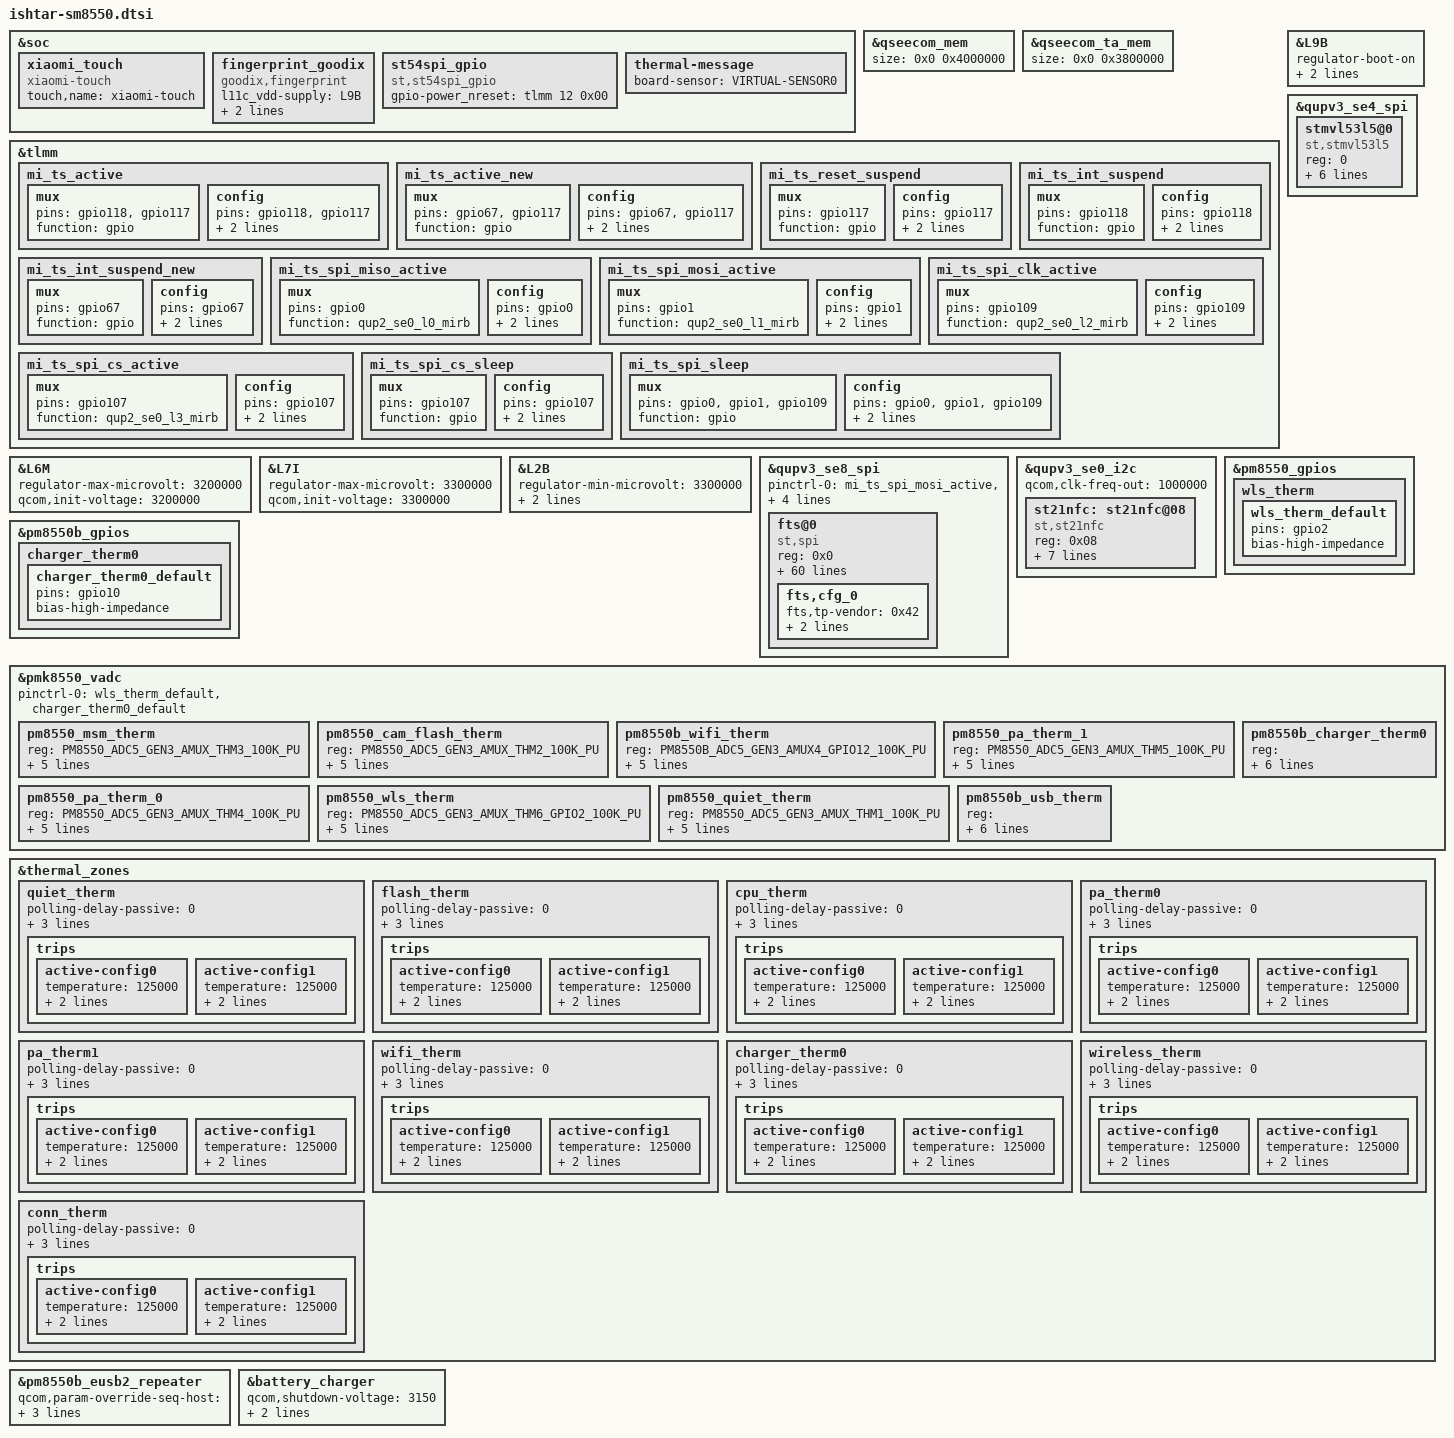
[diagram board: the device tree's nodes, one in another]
/*
  this file is for attribution only of zeus
  And public attribution of xiaomi platforms(like M1 and so and)
*/
#define ISHTAR_REGULATOR_OCP
#include "ishtar-pinctrl.dtsi"
#include "xiaomi-sm8550-common.dtsi"
#include <dt-bindings/clock/qcom,rpmh.h>

&soc {
	xiaomi_touch {
		compatible = "xiaomi-touch";
		status = "ok";
		touch,name = "xiaomi-touch";
	};
	fingerprint_goodix {
		compatible = "goodix,fingerprint";
		l11c_vdd-supply = <&L9B>;
		goodix,gpio-reset = <&tlmm 41 0x0>;
		goodix,gpio-irq = <&tlmm 40 0x0>;
		status = "ok";
	};
	st54spi_gpio {
		status = "ok";
		compatible = "st,st54spi_gpio";
		/* gpio used as SE_nRESET */
		gpio-power_nreset = <&tlmm 12 0x00>;
	};
};

&qseecom_mem {
		size = <0x0 0x4000000>;
};

&qseecom_ta_mem {
		size = <0x0 0x3800000>;
};

&tlmm {
	mi_ts_active: mi_ts_active {
		mux {
				pins = "gpio118", "gpio117";
				function = "gpio";
		};
		config {
				pins = "gpio118", "gpio117";
				drive-strength = <8>;
				bias-pull-up;
		};
	};

	mi_ts_active_new: mi_ts_active_new {
		mux {
				pins = "gpio67", "gpio117";
				function = "gpio";
		};
		config {
				pins = "gpio67", "gpio117";
				drive-strength = <8>;
				bias-pull-up;
		};
	};

	mi_ts_reset_suspend: mi_ts_reset_suspend {
		mux {
				pins = "gpio117";
				function = "gpio";
			};

		config {
				pins = "gpio117";
				drive-strength = <2>;
				bias-pull-down;
			};
	};

	mi_ts_int_suspend: mi_ts_int_suspend {
			mux {
				pins = "gpio118";
				function = "gpio";
			};

			config {
				pins = "gpio118";
				drive-strength = <2>;
				bias-pull-down;
			};
		};

	mi_ts_int_suspend_new: mi_ts_int_suspend_new {
		mux {
			pins = "gpio67";
			function = "gpio";
		};

		config {
			pins = "gpio67";
			drive-strength = <2>;
			bias-pull-down;
		};
	};

	mi_ts_spi_miso_active: mi_ts_spi_miso_active {
		mux {
			pins = "gpio0";
			function = "qup2_se0_l0_mirb";
		};
		config {
			pins = "gpio0";
			drive-strength = <6>;
			bias-pull-down;
		};
	};

	mi_ts_spi_mosi_active: mi_ts_spi_mosi_active {
		mux {
			pins = "gpio1";
			function = "qup2_se0_l1_mirb";
		};
		config {
			pins = "gpio1";
			drive-strength = <6>;
			bias-pull-down;
		};
	};

	mi_ts_spi_clk_active: mi_ts_spi_clk_active {
		mux {
			pins = "gpio109";
			function = "qup2_se0_l2_mirb";
		};
		config {
			pins = "gpio109";
			drive-strength = <6>;
			bias-pull-down;
		};
	};

	mi_ts_spi_cs_active: mi_ts_spi_cs_active {
		mux {
			pins = "gpio107";
			function = "qup2_se0_l3_mirb";
		};
		config {
			pins = "gpio107";
			drive-strength = <6>;
			bias-pull-down;
		};
	};

	mi_ts_spi_cs_sleep: mi_ts_spi_cs_sleep {
		mux {
			pins = "gpio107";
			function = "gpio";
		};
		config {
			pins =  "gpio107";
			drive-strength = <2>;
			bias-pull-up;
		};
	};

	mi_ts_spi_sleep: mi_ts_spi_sleep {
		mux {
			pins = "gpio0", "gpio1",
				"gpio109";
			function = "gpio";
		};
		config {
			pins = "gpio0", "gpio1",
				"gpio109";
			drive-strength = <2>;
			bias-pull-down;
		};
	};
};

&L9B {
	regulator-boot-on;
	regulator-always-on;
	qcom,init-voltage = <3008000>;
};

&L6M {
	regulator-max-microvolt = <3200000>;
	qcom,init-voltage = <3200000>;
};

&L7I {
	regulator-max-microvolt = <3300000>;
	qcom,init-voltage = <3300000>;
};

&L2B {
	regulator-min-microvolt = <3300000>;
	regulator-max-microvolt = <3300000>;
	qcom,init-voltage = <3300000>;
};

&qupv3_se4_spi {
	status = "ok";
	stmvl53l5@0 {
		compatible = "st,stmvl53l5";
		reg = <0>;
		_1P8_power-supply = <&L1B>;
		_3P0_power-supply = <&L2B>;
		spi-max-frequency = <8000000>;
		stm,interrupt = <&tlmm 85 1>;
		stm,l8_firmware_name = "stmvl53l8.bin";
		stm,l5_firmware_name = "stmvl53l5.bin";
		status = "ok";
	};
};



&qupv3_se8_spi {
	status = "ok";
	pinctrl-0 = <&mi_ts_spi_mosi_active>, <&mi_ts_spi_miso_active>,
				<&mi_ts_spi_clk_active>, <&mi_ts_spi_cs_active>;
	pinctrl-1 = <&mi_ts_spi_sleep>, <&mi_ts_spi_cs_sleep>;
	qcom,rt;
	fts@0 {
		status = "ok";
		compatible = "st,spi";
		reg = <0x0>;
		interrupt-parent = <&tlmm>;
		interrupts = <118 0x2008>;
		pinctrl-names = "pmx_ts_active", "pmx_ts_suspend", "pmx_ts_active_new", "pmx_ts_suspend_new";
		pinctrl-0 = <&mi_ts_active>;
		pinctrl-1 = <&mi_ts_int_suspend &mi_ts_reset_suspend>;
		pinctrl-2 = <&mi_ts_active_new>;
		pinctrl-3 = <&mi_ts_int_suspend_new &mi_ts_reset_suspend>;
		avdd-supply = <&L7I>;
		vdd-supply = <&L12B>;
		/*panel = <&dsi_k8_42_02_0a_dsc_cmd>;*/
		fts,pwr-reg-name = "avdd";
		fts,bus-reg-name = "vdd";
		fts,irq-gpio = <&tlmm  118 0x2008>;
		fts,irq-gpio,new = <&tlmm  67 0x2008>;
		fts,irq-gpio-name = "fts_irq";
		fts,reset-gpio-enable;
		fts,reset-gpio = <&tlmm 117 0x00>;
		fts,reset-gpio-name = "fts_rst";
		fts,irq-flags = <0x2008>;
		fts,x-max = <14400>;
		fts,y-max = <32000>;
		fts,fod-lx = <5850>;
		fts,fod-ly = <24060>;
		fts,fod-x-size = <2710>;
		fts,fod-y-size = <2710>;
		fts,support-fod;
		fts,support-thp;
		fts,support-thp-fw;
		spi-max-frequency = <12000000>;
		fts,support-super-resolution = <1>;
		fts,default-fw-name = "st_fts_m1.ftb";
		fts,config-array-size = <1>;
		fts,touch-follow-performance-def = <3>;
		fts,touch-tap-sensitivity-def = <4>;
		fts,touch-aim-sensitivity-def = <3>;
		fts,touch-tap-stability-def = <3>;
		fts,cornerfilter-area-step1 = <150>;
		fts,cornerfilter-area-step2 = <280>;
		fts,cornerfilter-area-step3 = <400>;
		fts,touch-deadzone-filter-ver = <2 0 0 0 0 0 0 0
										2 1 0 0 0 0 0 0
										2 2 0 0 0 3199 0 0
										2 3 1439 0 1439 3199 0 0>;
		fts,touch-deadzone-filter-hor = <2 0 0 0 1439 7 0 0
										2 1 0 3192 1439 3199 0 0
										2 2 0 0 0 3199 0 0
										2 3 1439 0 1439 3199 0 0>;
		fts,touch-edgezone-filter-ver = <1 0 0 0 0 0 0 0
										1 1 0 0 0 0 0 0
										1 2 0 0 60 3199 0 0
										1 3 1379 0 1439 3199 0 0>;
		fts,touch-edgezone-filter-hor = <1 0 0 0 1439 70 0 0
										1 1 0 3129 1439 3199 0 0
										1 2 0 0 60 3199 0 0
										1 3 1379 0 1439 3199 0 0>;
		fts,touch-cornerzone-filter-ver = <0 0 0 0 0 0 0 0
										0 1 0 0 0 0 0 0
										0 2 0 2799 250 3199 0 0
										0 3 1189 2799 1439 3199 0 0>;
		fts,touch-cornerzone-filter-hor1 = <0 0 0 0 280 280 0 0
										0 1 0 0 0 0 0 0
										0 2 0 2919 280 3199 0 0
										0 3 0 0 0 0 0 0>;
		fts,touch-cornerzone-filter-hor2 = <0 0 0 0 0 0 0 0
										0 1 1159 0 1439 280 0 0
										0 2 0 0 0 0 0 0
										0 3 1159 2919 1439 3199 0 0>;
		fts,touch-follow-performance = <10 15 1
										8 15 1
										6 15 1
										4 15 1
										2 15 1>;
		fts,touch-tap-sensitivity = <160 150 140 120 100>;
		fts,touch-aim-sensitivity = <10 8 6 4 2>;
		fts,touch-tap-stability = <8 12 15 18 25>;
		fts,touch-expert-array = <6 15 1 120 6 15
								  2 15 1 120 4 15
								  4 15 1 120 2 15>;
			fts,cfg_0 {
			fts,tp-vendor = <0x42>;
			fts,fw-name = "st_fts_m1.ftb";
			fts,limit-name = "stm_fts_production_limits.csv";
		};
	};
};


&qupv3_se0_i2c {
	status = "ok";
	qcom,clk-freq-out = <1000000>;
	#address-cells = <1>;
	#size-cells = <0>;
	st21nfc: st21nfc@08 {
		compatible = "st,st21nfc";
		reg = <0x08>;
		irq-gpios = <&tlmm 55 0x00>;
		reset-gpios = <&tlmm 30 0x00>;
		clkreq-gpios = <&tlmm 31 0x00>;
		interrupt-parent = <&tlmm>;
		interrupts = <55 0>;
		interrupt-names = "nfc_irq";
		pinctrl-names = "nfc_active", "nfc_suspend";
		pinctrl-0 = <&nfc_int_active &nfc_enable_active>;
		pinctrl-1 = <&nfc_int_suspend &nfc_enable_suspend>;
	};
};

&pm8550_gpios {
	wls_therm {
		wls_therm_default: wls_therm_default {
		pins = "gpio2";
		bias-high-impedance;
	};
	};
};

&pm8550b_gpios {
	charger_therm0 {
		charger_therm0_default: charger_therm0_default {
		pins = "gpio10";
		bias-high-impedance;
	};
	};
};

&pmk8550_vadc {
	pinctrl-names = "default";
	pinctrl-0 = <&wls_therm_default>, <&charger_therm0_default>;
	pm8550_msm_therm {
		reg = <PM8550_ADC5_GEN3_AMUX_THM3_100K_PU>;
		label = "pm8550_msm_therm";
		qcom,ratiometric;
		qcom,hw-settle-time = <200>;
		qcom,pre-scaling = <1 1>;
		qcom,adc-tm-type = <1>;
	};

	pm8550_cam_flash_therm {
		reg = <PM8550_ADC5_GEN3_AMUX_THM2_100K_PU>;
		label = "pm8550_cam_flash_therm";
		qcom,ratiometric;
		qcom,hw-settle-time = <200>;
		qcom,pre-scaling = <1 1>;
		qcom,adc-tm-type = <1>;
	};

	pm8550b_wifi_therm {
		reg = <PM8550B_ADC5_GEN3_AMUX4_GPIO12_100K_PU>;
		label = "pm8550b_wifi_therm";
		qcom,ratiometric;
		qcom,hw-settle-time = <200>;
		qcom,pre-scaling = <1 1>;
		qcom,adc-tm-type = <1>;
	};

	pm8550_pa_therm_1 {
		reg = <PM8550_ADC5_GEN3_AMUX_THM5_100K_PU>;
		label = "pm8550_pa_therm_1";
		qcom,ratiometric;
		qcom,hw-settle-time = <200>;
		qcom,pre-scaling = <1 1>;
		qcom,adc-tm-type = <1>;
	};

	pm8550_pa_therm_0 {
		reg = <PM8550_ADC5_GEN3_AMUX_THM4_100K_PU>;
		label = "pm8550_pa_therm_0";
		qcom,ratiometric;
		qcom,hw-settle-time = <200>;
		qcom,pre-scaling = <1 1>;
		qcom,adc-tm-type = <1>;
	};

	pm8550_wls_therm {
		reg = <PM8550_ADC5_GEN3_AMUX_THM6_GPIO2_100K_PU>;
		label = "pm8550_wls_therm";
		qcom,ratiometric;
		qcom,hw-settle-time = <200>;
		qcom,pre-scaling = <1 1>;
		qcom,adc-tm-type = <1>;
	};

	pm8550b_charger_therm0 {
		reg = <PM8550B_ADC5_GEN3_AMUX_THM6_GPIO10_100K_PU>;
		label = "pm8550b_charger_therm0";
		qcom,ratiometric;
		qcom,hw-settle-time = <200>;
		qcom,pre-scaling = <1 1>;
		qcom,adc-tm-type = <1>;
	};

	pm8550_quiet_therm {
		reg = <PM8550_ADC5_GEN3_AMUX_THM1_100K_PU>;
		label = "pm8550_quiet_therm";
		qcom,ratiometric;
		qcom,hw-settle-time = <200>;
		qcom,pre-scaling = <1 1>;
		qcom,adc-tm-type = <1>;
	};

	pm8550b_usb_therm {
		reg = <PM8550B_ADC5_GEN3_AMUX_THM4_USB_THERM_100K_PU>;
		label = "pm8550b_usb_therm";
		qcom,ratiometric;
		qcom,hw-settle-time = <200>;
		qcom,pre-scaling = <1 1>;
		qcom,adc-tm-type = <1>;
	};
};

&thermal_zones {
	quiet_therm {
		polling-delay-passive = <0>;
		polling-delay = <0>;
		thermal-sensors = <&pmk8550_vadc PM8550_ADC5_GEN3_AMUX_THM1_100K_PU>;
		trips {
			active-config0 {
				temperature = <125000>;
				hysteresis = <1000>;
				type = "passive";
			};

			active-config1 {
				temperature = <125000>;
				hysteresis = <1000>;
				type = "passive";
			};
		};
	};

	flash_therm {
		polling-delay-passive = <0>;
		polling-delay = <0>;
		thermal-sensors = <&pmk8550_vadc PM8550_ADC5_GEN3_AMUX_THM2_100K_PU>;
		trips {
			active-config0 {
				temperature = <125000>;
				hysteresis = <1000>;
				type = "passive";
			};

			active-config1 {
				temperature = <125000>;
				hysteresis = <1000>;
				type = "passive";
			};
		};
	};

	cpu_therm {
		polling-delay-passive = <0>;
		polling-delay = <0>;
		thermal-sensors = <&pmk8550_vadc PM8550_ADC5_GEN3_AMUX_THM3_100K_PU>;
		trips {
			active-config0 {
				temperature = <125000>;
				hysteresis = <1000>;
				type = "passive";
			};

			active-config1 {
				temperature = <125000>;
				hysteresis = <1000>;
				type = "passive";
			};
		};
	};

	pa_therm0 {
		polling-delay-passive = <0>;
		polling-delay = <0>;
		thermal-sensors = <&pmk8550_vadc PM8550_ADC5_GEN3_AMUX_THM4_100K_PU>;
		trips {
			active-config0 {
				temperature = <125000>;
				hysteresis = <1000>;
				type = "passive";
			};

			active-config1 {
				temperature = <125000>;
				hysteresis = <1000>;
				type = "passive";
			};
		};
	};

	pa_therm1 {
		polling-delay-passive = <0>;
		polling-delay = <0>;
		thermal-sensors = <&pmk8550_vadc PM8550_ADC5_GEN3_AMUX_THM5_100K_PU>;
		trips {
			active-config0 {
				temperature = <125000>;
				hysteresis = <1000>;
				type = "passive";
			};

			active-config1 {
				temperature = <125000>;
				hysteresis = <1000>;
				type = "passive";
			};
		};
	};

	wifi_therm {
		polling-delay-passive = <0>;
		polling-delay = <0>;
		thermal-sensors = <&pmk8550_vadc PM8550B_ADC5_GEN3_AMUX4_GPIO12_100K_PU>;
		trips {
			active-config0 {
				temperature = <125000>;
				hysteresis = <1000>;
				type = "passive";
			};

			active-config1 {
				temperature = <125000>;
				hysteresis = <1000>;
				type = "passive";
			};
		};
	};

	charger_therm0 {
		polling-delay-passive = <0>;
		polling-delay = <0>;
		thermal-sensors = <&pmk8550_vadc PM8550B_ADC5_GEN3_AMUX_THM6_GPIO10_100K_PU>;
		trips {
			active-config0 {
				temperature = <125000>;
				hysteresis = <1000>;
				type = "passive";
			};

			active-config1 {
				temperature = <125000>;
				hysteresis = <1000>;
				type = "passive";
			};
		};
	};

	wireless_therm {
		polling-delay-passive = <0>;
		polling-delay = <0>;
		thermal-sensors = <&pmk8550_vadc PM8550_ADC5_GEN3_AMUX_THM6_GPIO2_100K_PU>;
		trips {
			active-config0 {
				temperature = <125000>;
				hysteresis = <1000>;
				type = "passive";
			};

			active-config1 {
				temperature = <125000>;
				hysteresis = <1000>;
				type = "passive";
			};
		};
	};

	conn_therm {
		polling-delay-passive = <0>;
		polling-delay = <0>;
		thermal-sensors = <&pmk8550_vadc PM8550B_ADC5_GEN3_AMUX_THM4_USB_THERM_100K_PU>;
		trips {
			active-config0 {
				temperature = <125000>;
				hysteresis = <1000>;
				type = "passive";
			};

			active-config1 {
				temperature = <125000>;
				hysteresis = <1000>;
				type = "passive";
			};
		};
	};
};

&soc {
	thermal-message {
		board-sensor = "VIRTUAL-SENSOR0";
	};
};

&pm8550b_eusb2_repeater {
	qcom,param-override-seq-host =
		<0x00 0x50
		0x0F 0x51
		0x03 0x52
                0x06 0x53
		0x02 0x54
		0x01 0x55
		0x00 0x56
		0x07 0x57>;
	qcom,param-override-seq =
		<0x00 0x50
		0x0E 0x51
		0x03 0x52
		0x06 0x53
		0x02 0x54
		0x01 0x55
		0x00 0x56
		0x07 0x57>;
};
&battery_charger {
	qcom,shutdown-voltage = <3150>;
	mi,support-shutdown-delay;
        mi,support-extreme-mode;
};
